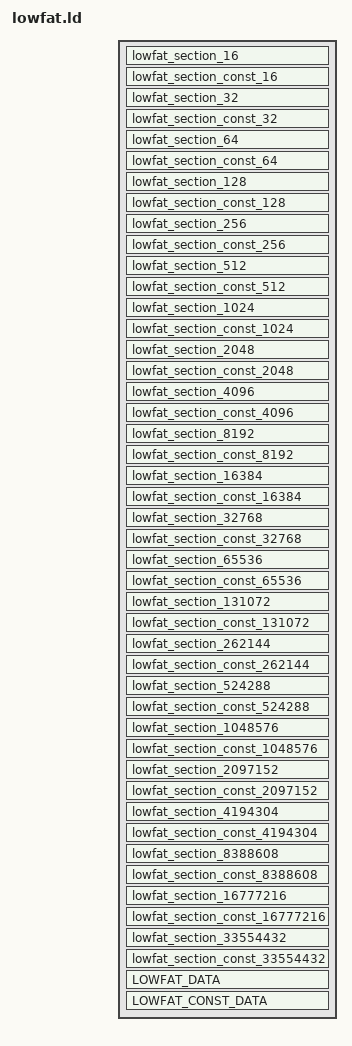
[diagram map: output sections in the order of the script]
/* AUTOMATICALLY GENERATED */

SECTIONS
{
	. = 0xbffff7000 + SIZEOF_HEADERS;
	lowfat_section_16 :
	{
		KEEP(*(lowfat_section_16))
	}
	ASSERT(. < 0xcffff7000, "Lowfat section (lowfat_section_16) is too big; max size is 2GB")
	. = 0xcffff7000 + SIZEOF_HEADERS;
	lowfat_section_const_16 :
	{
		KEEP(*(lowfat_section_const_16))
	}
	ASSERT(. < 0xdffff7000, "Lowfat section (lowfat_const_section_16) is too big; max size is 2GB")
	. = 0x13ffff7000 + SIZEOF_HEADERS;
	lowfat_section_32 :
	{
		KEEP(*(lowfat_section_32))
	}
	ASSERT(. < 0x14ffff7000, "Lowfat section (lowfat_section_32) is too big; max size is 2GB")
	. = 0x14ffff7000 + SIZEOF_HEADERS;
	lowfat_section_const_32 :
	{
		KEEP(*(lowfat_section_const_32))
	}
	ASSERT(. < 0x15ffff7000, "Lowfat section (lowfat_const_section_32) is too big; max size is 2GB")
	. = 0x1bffff7000 + SIZEOF_HEADERS;
	lowfat_section_64 :
	{
		KEEP(*(lowfat_section_64))
	}
	ASSERT(. < 0x1cffff7000, "Lowfat section (lowfat_section_64) is too big; max size is 2GB")
	. = 0x1cffff7000 + SIZEOF_HEADERS;
	lowfat_section_const_64 :
	{
		KEEP(*(lowfat_section_const_64))
	}
	ASSERT(. < 0x1dffff7000, "Lowfat section (lowfat_const_section_64) is too big; max size is 2GB")
	. = 0x23ffff7000 + SIZEOF_HEADERS;
	lowfat_section_128 :
	{
		KEEP(*(lowfat_section_128))
	}
	ASSERT(. < 0x24ffff7000, "Lowfat section (lowfat_section_128) is too big; max size is 2GB")
	. = 0x24ffff7000 + SIZEOF_HEADERS;
	lowfat_section_const_128 :
	{
		KEEP(*(lowfat_section_const_128))
	}
	ASSERT(. < 0x25ffff7000, "Lowfat section (lowfat_const_section_128) is too big; max size is 2GB")
	. = 0x2bffff7000 + SIZEOF_HEADERS;
	lowfat_section_256 :
	{
		KEEP(*(lowfat_section_256))
	}
	ASSERT(. < 0x2cffff7000, "Lowfat section (lowfat_section_256) is too big; max size is 2GB")
	. = 0x2cffff7000 + SIZEOF_HEADERS;
	lowfat_section_const_256 :
	{
		KEEP(*(lowfat_section_const_256))
	}
	ASSERT(. < 0x2dffff7000, "Lowfat section (lowfat_const_section_256) is too big; max size is 2GB")
	. = 0x33ffff7000 + SIZEOF_HEADERS;
	lowfat_section_512 :
	{
		KEEP(*(lowfat_section_512))
	}
	ASSERT(. < 0x34ffff7000, "Lowfat section (lowfat_section_512) is too big; max size is 2GB")
	. = 0x34ffff7000 + SIZEOF_HEADERS;
	lowfat_section_const_512 :
	{
		KEEP(*(lowfat_section_const_512))
	}
	ASSERT(. < 0x35ffff7000, "Lowfat section (lowfat_const_section_512) is too big; max size is 2GB")
	. = 0x3bffff7000 + SIZEOF_HEADERS;
	lowfat_section_1024 :
	{
		KEEP(*(lowfat_section_1024))
	}
	ASSERT(. < 0x3cffff7000, "Lowfat section (lowfat_section_1024) is too big; max size is 2GB")
	. = 0x3cffff7000 + SIZEOF_HEADERS;
	lowfat_section_const_1024 :
	{
		KEEP(*(lowfat_section_const_1024))
	}
	ASSERT(. < 0x3dffff7000, "Lowfat section (lowfat_const_section_1024) is too big; max size is 2GB")
	. = 0x43ffff7000 + SIZEOF_HEADERS;
	lowfat_section_2048 :
	{
		KEEP(*(lowfat_section_2048))
	}
	ASSERT(. < 0x44ffff7000, "Lowfat section (lowfat_section_2048) is too big; max size is 2GB")
	. = 0x44ffff7000 + SIZEOF_HEADERS;
	lowfat_section_const_2048 :
	{
		KEEP(*(lowfat_section_const_2048))
	}
	ASSERT(. < 0x45ffff7000, "Lowfat section (lowfat_const_section_2048) is too big; max size is 2GB")
	. = 0x4bffff7000 + SIZEOF_HEADERS;
	lowfat_section_4096 :
	{
		KEEP(*(lowfat_section_4096))
	}
	ASSERT(. < 0x4cffff7000, "Lowfat section (lowfat_section_4096) is too big; max size is 2GB")
	. = 0x4cffff7000 + SIZEOF_HEADERS;
	lowfat_section_const_4096 :
	{
		KEEP(*(lowfat_section_const_4096))
	}
	ASSERT(. < 0x4dffff7000, "Lowfat section (lowfat_const_section_4096) is too big; max size is 2GB")
	. = 0x53ffff7000 + SIZEOF_HEADERS;
	lowfat_section_8192 :
	{
		KEEP(*(lowfat_section_8192))
	}
	ASSERT(. < 0x54ffff7000, "Lowfat section (lowfat_section_8192) is too big; max size is 2GB")
	. = 0x54ffff7000 + SIZEOF_HEADERS;
	lowfat_section_const_8192 :
	{
		KEEP(*(lowfat_section_const_8192))
	}
	ASSERT(. < 0x55ffff7000, "Lowfat section (lowfat_const_section_8192) is too big; max size is 2GB")
	. = 0x5bffff7000 + SIZEOF_HEADERS;
	lowfat_section_16384 :
	{
		KEEP(*(lowfat_section_16384))
	}
	ASSERT(. < 0x5cffff7000, "Lowfat section (lowfat_section_16384) is too big; max size is 2GB")
	. = 0x5cffff7000 + SIZEOF_HEADERS;
	lowfat_section_const_16384 :
	{
		KEEP(*(lowfat_section_const_16384))
	}
	ASSERT(. < 0x5dffff7000, "Lowfat section (lowfat_const_section_16384) is too big; max size is 2GB")
	. = 0x63ffff7000 + SIZEOF_HEADERS;
	lowfat_section_32768 :
	{
		KEEP(*(lowfat_section_32768))
	}
	ASSERT(. < 0x64ffff7000, "Lowfat section (lowfat_section_32768) is too big; max size is 2GB")
	. = 0x64ffff7000 + SIZEOF_HEADERS;
	lowfat_section_const_32768 :
	{
		KEEP(*(lowfat_section_const_32768))
	}
	ASSERT(. < 0x65ffff7000, "Lowfat section (lowfat_const_section_32768) is too big; max size is 2GB")
	. = 0x6bffff7000 + SIZEOF_HEADERS;
	lowfat_section_65536 :
	{
		KEEP(*(lowfat_section_65536))
	}
	ASSERT(. < 0x6cffff7000, "Lowfat section (lowfat_section_65536) is too big; max size is 2GB")
	. = 0x6cffff7000 + SIZEOF_HEADERS;
	lowfat_section_const_65536 :
	{
		KEEP(*(lowfat_section_const_65536))
	}
	ASSERT(. < 0x6dffff7000, "Lowfat section (lowfat_const_section_65536) is too big; max size is 2GB")
	. = 0x73ffff7000 + SIZEOF_HEADERS;
	lowfat_section_131072 :
	{
		KEEP(*(lowfat_section_131072))
	}
	ASSERT(. < 0x74ffff7000, "Lowfat section (lowfat_section_131072) is too big; max size is 2GB")
	. = 0x74ffff7000 + SIZEOF_HEADERS;
	lowfat_section_const_131072 :
	{
		KEEP(*(lowfat_section_const_131072))
	}
	ASSERT(. < 0x75ffff7000, "Lowfat section (lowfat_const_section_131072) is too big; max size is 2GB")
	. = 0x7bffff7000 + SIZEOF_HEADERS;
	lowfat_section_262144 :
	{
		KEEP(*(lowfat_section_262144))
	}
	ASSERT(. < 0x7cffff7000, "Lowfat section (lowfat_section_262144) is too big; max size is 2GB")
	. = 0x7cffff7000 + SIZEOF_HEADERS;
	lowfat_section_const_262144 :
	{
		KEEP(*(lowfat_section_const_262144))
	}
	ASSERT(. < 0x7dffff7000, "Lowfat section (lowfat_const_section_262144) is too big; max size is 2GB")
	. = 0x83ffff7000 + SIZEOF_HEADERS;
	lowfat_section_524288 :
	{
		KEEP(*(lowfat_section_524288))
	}
	ASSERT(. < 0x84ffff7000, "Lowfat section (lowfat_section_524288) is too big; max size is 2GB")
	. = 0x84ffff7000 + SIZEOF_HEADERS;
	lowfat_section_const_524288 :
	{
		KEEP(*(lowfat_section_const_524288))
	}
	ASSERT(. < 0x85ffff7000, "Lowfat section (lowfat_const_section_524288) is too big; max size is 2GB")
	. = 0x8bffff7000 + SIZEOF_HEADERS;
	lowfat_section_1048576 :
	{
		KEEP(*(lowfat_section_1048576))
	}
	ASSERT(. < 0x8cffff7000, "Lowfat section (lowfat_section_1048576) is too big; max size is 2GB")
	. = 0x8cffff7000 + SIZEOF_HEADERS;
	lowfat_section_const_1048576 :
	{
		KEEP(*(lowfat_section_const_1048576))
	}
	ASSERT(. < 0x8dffff7000, "Lowfat section (lowfat_const_section_1048576) is too big; max size is 2GB")
	. = 0x93ffff7000 + SIZEOF_HEADERS;
	lowfat_section_2097152 :
	{
		KEEP(*(lowfat_section_2097152))
	}
	ASSERT(. < 0x94ffff7000, "Lowfat section (lowfat_section_2097152) is too big; max size is 2GB")
	. = 0x94ffff7000 + SIZEOF_HEADERS;
	lowfat_section_const_2097152 :
	{
		KEEP(*(lowfat_section_const_2097152))
	}
	ASSERT(. < 0x95ffff7000, "Lowfat section (lowfat_const_section_2097152) is too big; max size is 2GB")
	. = 0x9bffff7000 + SIZEOF_HEADERS;
	lowfat_section_4194304 :
	{
		KEEP(*(lowfat_section_4194304))
	}
	ASSERT(. < 0x9cffff7000, "Lowfat section (lowfat_section_4194304) is too big; max size is 2GB")
	. = 0x9cffff7000 + SIZEOF_HEADERS;
	lowfat_section_const_4194304 :
	{
		KEEP(*(lowfat_section_const_4194304))
	}
	ASSERT(. < 0x9dffff7000, "Lowfat section (lowfat_const_section_4194304) is too big; max size is 2GB")
	. = 0xa3ffff7000 + SIZEOF_HEADERS;
	lowfat_section_8388608 :
	{
		KEEP(*(lowfat_section_8388608))
	}
	ASSERT(. < 0xa4ffff7000, "Lowfat section (lowfat_section_8388608) is too big; max size is 2GB")
	. = 0xa4ffff7000 + SIZEOF_HEADERS;
	lowfat_section_const_8388608 :
	{
		KEEP(*(lowfat_section_const_8388608))
	}
	ASSERT(. < 0xa5ffff7000, "Lowfat section (lowfat_const_section_8388608) is too big; max size is 2GB")
	. = 0xabffff7000 + SIZEOF_HEADERS;
	lowfat_section_16777216 :
	{
		KEEP(*(lowfat_section_16777216))
	}
	ASSERT(. < 0xacffff7000, "Lowfat section (lowfat_section_16777216) is too big; max size is 2GB")
	. = 0xacffff7000 + SIZEOF_HEADERS;
	lowfat_section_const_16777216 :
	{
		KEEP(*(lowfat_section_const_16777216))
	}
	ASSERT(. < 0xadffff7000, "Lowfat section (lowfat_const_section_16777216) is too big; max size is 2GB")
	. = 0xb3ffff7000 + SIZEOF_HEADERS;
	lowfat_section_33554432 :
	{
		KEEP(*(lowfat_section_33554432))
	}
	ASSERT(. < 0xb4ffff7000, "Lowfat section (lowfat_section_33554432) is too big; max size is 2GB")
	. = 0xb4ffff7000 + SIZEOF_HEADERS;
	lowfat_section_const_33554432 :
	{
		KEEP(*(lowfat_section_const_33554432))
	}
	ASSERT(. < 0xb5ffff7000, "Lowfat section (lowfat_const_section_33554432) is too big; max size is 2GB")
	. = 0x1f800000000 + SIZEOF_HEADERS;
	LOWFAT_DATA :
	{
		KEEP(*(LOWFAT_DATA))
	}
	. = 0x20000000000 + SIZEOF_HEADERS;
	LOWFAT_CONST_DATA :
	{
		KEEP(*(LOWFAT_CONST_DATA))
	}
}

INSERT AFTER .gnu.attributes;

